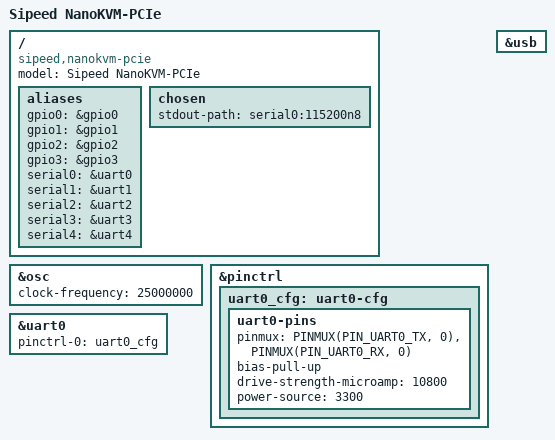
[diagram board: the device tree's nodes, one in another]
// SPDX-License-Identifier: (GPL-2.0 OR MIT)
/*
 * Copyright (C) 2024 Thomas Bonnefille <thomas.bonnefille@bootlin.com>
 */

/dts-v1/;

#include "sg2002.dtsi"

/ {
	model = "Sipeed NanoKVM-PCIe";
	compatible = "sipeed,nanokvm-pcie", "sophgo,sg2002";

	aliases {
		gpio0 = &gpio0;
		gpio1 = &gpio1;
		gpio2 = &gpio2;
		gpio3 = &gpio3;
		serial0 = &uart0;
		serial1 = &uart1;
		serial2 = &uart2;
		serial3 = &uart3;
		serial4 = &uart4;
	};

	chosen {
		stdout-path = "serial0:115200n8";
	};
};

&osc {
	clock-frequency = <25000000>;
};

&pinctrl {
	uart0_cfg: uart0-cfg {
		uart0-pins {
			pinmux = <PINMUX(PIN_UART0_TX, 0)>,
				 <PINMUX(PIN_UART0_RX, 0)>;
			bias-pull-up;
			drive-strength-microamp = <10800>;
			power-source = <3300>;
		};
	};
};

&uart0 {
	pinctrl-0 = <&uart0_cfg>;
	pinctrl-names = "default";
	status = "okay";
};

&usb {
	status = "okay";
};
